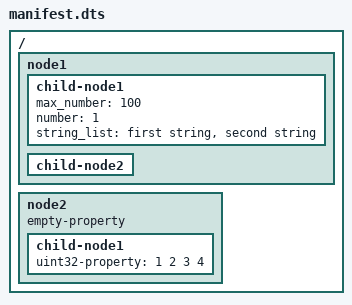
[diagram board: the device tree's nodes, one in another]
/dts-v1/;

// dtc -O dtb -o manifest.dtb manifest.dts
/ {
    node1 {
        child-node1 {
            // max_number must be parsed first so a single string
            // is stored for max_number and number with different offsets
            max_number = <100>;
            number = <1>;
            string_list = "first string", "second string";
        };
        child-node2 {
        };
    };
    node2 {
        empty-property;
        child-node1 {
            uint32-property = <1 2 3 4>;
        };
    };
};
